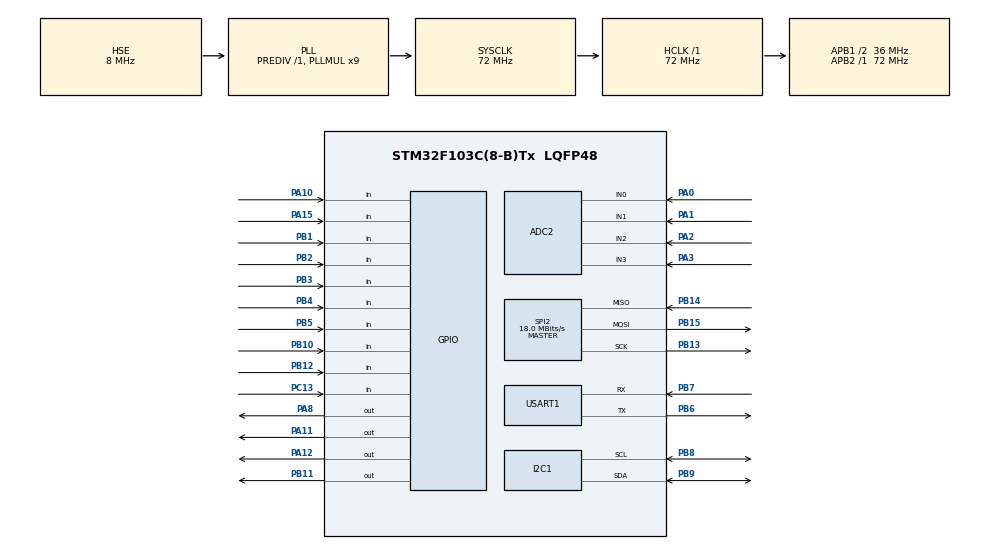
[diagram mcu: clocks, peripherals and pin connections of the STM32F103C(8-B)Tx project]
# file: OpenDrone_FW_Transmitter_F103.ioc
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ADC2.Channel-10\#ChannelRegularConversion=ADC_CHANNEL_2
ADC2.Channel-11\#ChannelRegularConversion=ADC_CHANNEL_3
ADC2.Channel-5\#ChannelRegularConversion=ADC_CHANNEL_0
ADC2.Channel-9\#ChannelRegularConversion=ADC_CHANNEL_1
ADC2.ContinuousConvMode=ENABLE
ADC2.EnableRegularConversion=ENABLE
ADC2.NbrOfConversion=4
ADC2.NbrOfConversionFlag=1
ADC2.Rank-10\#ChannelRegularConversion=3
ADC2.Rank-11\#ChannelRegularConversion=4
ADC2.Rank-5\#ChannelRegularConversion=1
ADC2.Rank-9\#ChannelRegularConversion=2
ADC2.SamplingTime-10\#ChannelRegularConversion=ADC_SAMPLETIME_13CYCLES_5
ADC2.SamplingTime-11\#ChannelRegularConversion=ADC_SAMPLETIME_13CYCLES_5
ADC2.SamplingTime-5\#ChannelRegularConversion=ADC_SAMPLETIME_13CYCLES_5
ADC2.SamplingTime-9\#ChannelRegularConversion=ADC_SAMPLETIME_13CYCLES_5
Mcu.Family=STM32F1
Mcu.Name=STM32F103C(8-B)Tx
Mcu.Package=LQFP48
NVIC.PriorityGroup=NVIC_PRIORITYGROUP_4
PA0-WKUP.Signal=ADCx_IN0
PA1.Signal=ADCx_IN1
PA10.Signal=GPIO_Input
PA11.Signal=GPIO_Output
PA12.Signal=GPIO_Output
PA13.Mode=Serial_Wire
PA13.Signal=SYS_JTMS-SWDIO
PA14.Mode=Serial_Wire
PA14.Signal=SYS_JTCK-SWCLK
PA15.GPIO_PuPd=GPIO_PULLUP
PA15.Signal=GPIO_Input
PA2.Signal=ADCx_IN2
PA3.Signal=ADCx_IN3
PA8.GPIO_Speed=GPIO_SPEED_FREQ_HIGH
PA8.PinState=GPIO_PIN_SET
PA8.Signal=GPIO_Output
PB1.Signal=GPIO_Input
PB10.Signal=GPIO_Input
PB11.GPIO_Speed=GPIO_SPEED_FREQ_HIGH
PB11.PinState=GPIO_PIN_SET
PB11.Signal=GPIO_Output
PB12.Signal=GPIO_Input
PB13.Mode=Full_Duplex_Master
PB13.Signal=SPI2_SCK
PB14.Mode=Full_Duplex_Master
PB14.Signal=SPI2_MISO
PB15.Mode=Full_Duplex_Master
PB15.Signal=SPI2_MOSI
PB2.Signal=GPIO_Input
PB3.Signal=GPIO_Input
PB4.Signal=GPIO_Input
PB5.Signal=GPIO_Input
PB6.Mode=Asynchronous
PB6.Signal=USART1_TX
PB7.Mode=Asynchronous
PB7.Signal=USART1_RX
PB8.Mode=I2C
PB8.Signal=I2C1_SCL
PB9.Mode=I2C
PB9.Signal=I2C1_SDA
PC13-TAMPER-RTC.Signal=GPIO_Input
PD0-OSC_IN.Mode=HSE-External-Oscillator
PD0-OSC_IN.Signal=RCC_OSC_IN
PD1-OSC_OUT.Mode=HSE-External-Oscillator
PD1-OSC_OUT.Signal=RCC_OSC_OUT
ProjectManager.HeapSize=0x200
ProjectManager.StackSize=0x400
ProjectManager.TargetToolchain=STM32CubeIDE
RCC.ADCPresc=RCC_ADCPCLK2_DIV6
RCC.AHBFreq_Value=72000000
RCC.APB1CLKDivider=RCC_HCLK_DIV2
RCC.APB1Freq_Value=36000000
RCC.APB1TimFreq_Value=72000000
RCC.APB2Freq_Value=72000000
RCC.APB2TimFreq_Value=72000000
RCC.HCLKFreq_Value=72000000
RCC.PLLMUL=RCC_PLL_MUL9
RCC.PLLSourceVirtual=RCC_PLLSOURCE_HSE
RCC.SYSCLKFreq_VALUE=72000000
RCC.SYSCLKSource=RCC_SYSCLKSOURCE_PLLCLK
RCC.USBFreq_Value=72000000
SH.ADCx_IN0.0=ADC2_IN0,IN0
SH.ADCx_IN1.0=ADC2_IN1,IN1
SH.ADCx_IN2.0=ADC2_IN2,IN2
SH.ADCx_IN3.0=ADC2_IN3,IN3
SPI2.CalculateBaudRate=18.0 MBits/s
SPI2.Direction=SPI_DIRECTION_2LINES
SPI2.Mode=SPI_MODE_MASTER
SPI2.VirtualType=VM_MASTER
TIM2.AutoReloadPreload=TIM_AUTORELOAD_PRELOAD_DISABLE
TIM2.Prescaler=71
USART1.VirtualMode=VM_ASYNC
VP_TIM2_VS_ClockSourceINT.Mode=Internal
board=custom

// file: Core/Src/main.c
/* USER CODE BEGIN Header */
/**
  ******************************************************************************
  * @file           : main.c
  * @brief          : Main program body
  ******************************************************************************
  * @attention
  *
  * Copyright (c) 2024 STMicroelectronics.
  * All rights reserved.
  *
  * This software is licensed under terms that can be found in the LICENSE file
  * in the root directory of this software component.
  * If no LICENSE file comes with this software, it is provided AS-IS.
  *
  ******************************************************************************
  */
/* USER CODE END Header */
#include "main.h"
#include "adc.h"
#include "i2c.h"
#include "spi.h"
#include "tim.h"
#include "usart.h"
#include "gpio.h"

/* USER CODE BEGIN Includes */
#include "OpenDrone_Transmitter.h"
/* USER CODE END Includes */

void SystemClock_Config(void);

int main(void)
{

  /* MCU Configuration--------------------------------------------------------*/

  /* Reset of all peripherals, Initializes the Flash interface and the Systick. */
  HAL_Init();

  /* Configure the system clock */
  SystemClock_Config();

  /* Initialize all configured peripherals */
  MX_GPIO_Init();
  MX_I2C1_Init();
  MX_TIM2_Init();
  MX_ADC2_Init();
  MX_SPI2_Init();
  MX_USART1_UART_Init();
  /* USER CODE BEGIN 2 */
    OpenDrone_Transmitter_Init();
  /* USER CODE END 2 */

  /* Infinite loop */
  /* USER CODE BEGIN WHILE */
    while (1)
    {
        OpenDrone_Transmitter_Main();
    /* USER CODE END WHILE */

    }
}

void SystemClock_Config(void)
{
  RCC_OscInitTypeDef RCC_OscInitStruct = {0};
  RCC_ClkInitTypeDef RCC_ClkInitStruct = {0};
  RCC_PeriphCLKInitTypeDef PeriphClkInit = {0};

  /** Initializes the RCC Oscillators according to the specified parameters
  * in the RCC_OscInitTypeDef structure.
  */
  RCC_OscInitStruct.OscillatorType = RCC_OSCILLATORTYPE_HSE;
  RCC_OscInitStruct.HSEState = RCC_HSE_ON;
  RCC_OscInitStruct.HSEPredivValue = RCC_HSE_PREDIV_DIV1;
  RCC_OscInitStruct.HSIState = RCC_HSI_ON;
  RCC_OscInitStruct.PLL.PLLState = RCC_PLL_ON;
  RCC_OscInitStruct.PLL.PLLSource = RCC_PLLSOURCE_HSE;
  RCC_OscInitStruct.PLL.PLLMUL = RCC_PLL_MUL9;
  if (HAL_RCC_OscConfig(&RCC_OscInitStruct) != HAL_OK)
  {
    Error_Handler();
  }

  /** Initializes the CPU, AHB and APB buses clocks
  */
  RCC_ClkInitStruct.ClockType = RCC_CLOCKTYPE_HCLK|RCC_CLOCKTYPE_SYSCLK
                              |RCC_CLOCKTYPE_PCLK1|RCC_CLOCKTYPE_PCLK2;
  RCC_ClkInitStruct.SYSCLKSource = RCC_SYSCLKSOURCE_PLLCLK;
  RCC_ClkInitStruct.AHBCLKDivider = RCC_SYSCLK_DIV1;
  RCC_ClkInitStruct.APB1CLKDivider = RCC_HCLK_DIV2;
  RCC_ClkInitStruct.APB2CLKDivider = RCC_HCLK_DIV1;

  if (HAL_RCC_ClockConfig(&RCC_ClkInitStruct, FLASH_LATENCY_2) != HAL_OK)
  {
    Error_Handler();
  }
  PeriphClkInit.PeriphClockSelection = RCC_PERIPHCLK_ADC;
  PeriphClkInit.AdcClockSelection = RCC_ADCPCLK2_DIV6;
  if (HAL_RCCEx_PeriphCLKConfig(&PeriphClkInit) != HAL_OK)
  {
    Error_Handler();
  }
}

void Error_Handler(void)
{
    __disable_irq();
    while (1)
    {
    }
}
